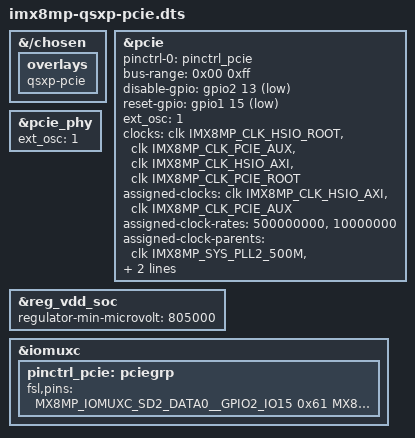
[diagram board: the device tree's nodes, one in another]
// SPDX-License-Identifier: (GPL-2.0 OR MIT)
/*
 * Copyright 2022 Lothar Waßmann <LW@KARO-electronics.de>
 *
 */

/dts-v1/;

/plugin/;

#include <dt-bindings/clock/imx8mp-clock.h>
#include <dt-bindings/gpio/gpio.h>
#include "imx8mp-pinfunc.h"

&{/chosen} {
	overlays {
		qsxp-pcie;
	};
};

&pcie {
	pinctrl-names = "default";
	pinctrl-0 = <&pinctrl_pcie>;
	bus-range = <0x00 0xff>;
	disable-gpio = <&gpio2 13 GPIO_ACTIVE_LOW>;
	reset-gpio = <&gpio1 15 GPIO_ACTIVE_LOW>;
	ext_osc = <1>;
	clocks = <&clk IMX8MP_CLK_HSIO_ROOT>,
		 <&clk IMX8MP_CLK_PCIE_AUX>,
		 <&clk IMX8MP_CLK_HSIO_AXI>,
		 <&clk IMX8MP_CLK_PCIE_ROOT>;
	clock-names = "pcie", "pcie_aux", "pcie_phy", "pcie_bus";
	assigned-clocks = <&clk IMX8MP_CLK_HSIO_AXI>,
			  <&clk IMX8MP_CLK_PCIE_AUX>;
	assigned-clock-rates = <500000000>, <10000000>;
	assigned-clock-parents = <&clk IMX8MP_SYS_PLL2_500M>,
				 <&clk IMX8MP_SYS_PLL2_50M>;
	l1ss-disabled;
	status = "okay";
};

&pcie_phy {
	ext_osc = <1>;
	status = "okay";
};

&reg_vdd_soc {
	/* PCIe requires a minimum vdd soc voltage of 0.805V */
	regulator-min-microvolt = <805000>;
};

&iomuxc {
	pinctrl_pcie: pciegrp {
		fsl,pins = <
			MX8MP_IOMUXC_SD2_DATA0__GPIO2_IO15	0x61 /* open drain, pull up */
			MX8MP_IOMUXC_SD2_CLK__GPIO2_IO13	0x41
			MX8MP_IOMUXC_GPIO1_IO15__GPIO1_IO15	0x41
		>;
	};
};
